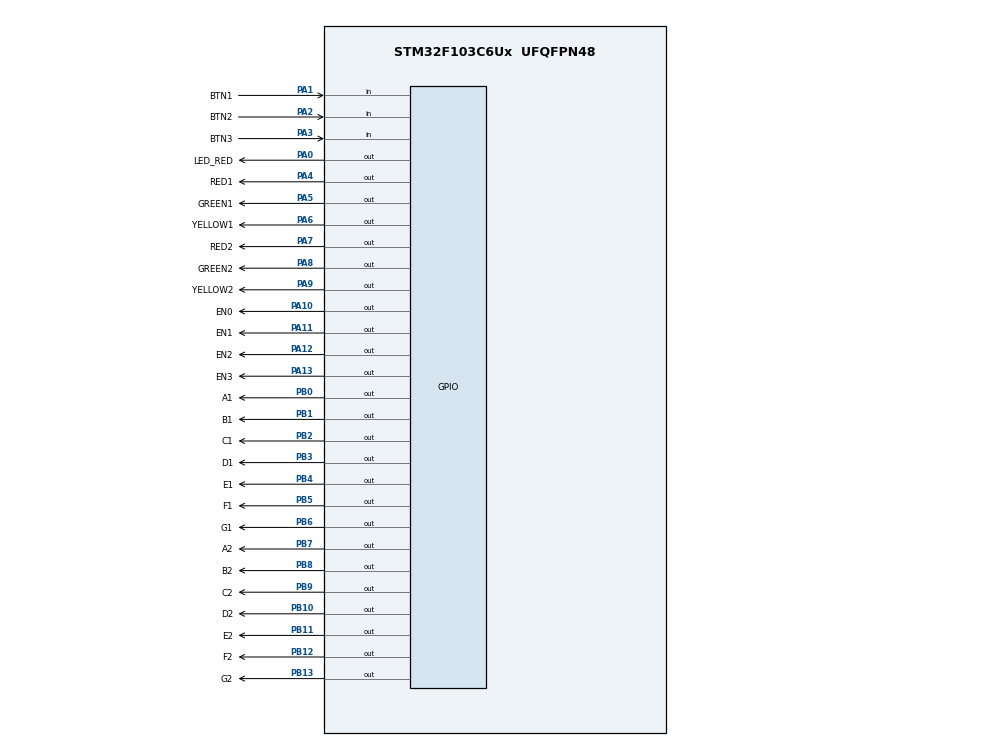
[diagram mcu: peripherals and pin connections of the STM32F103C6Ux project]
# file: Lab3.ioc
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Mcu.Family=STM32F1
Mcu.Name=STM32F103C6Ux
Mcu.Package=UFQFPN48
NVIC.PriorityGroup=NVIC_PRIORITYGROUP_4
NVIC.TIM2_IRQn=true\:0\:0\:false\:false\:true\:true\:true
PA0-WKUP.GPIO_Label=LED_RED
PA0-WKUP.Signal=GPIO_Output
PA1.GPIO_Label=BTN1
PA1.GPIO_PuPd=GPIO_PULLUP
PA1.Signal=GPIO_Input
PA10.GPIO_Label=EN0
PA10.Signal=GPIO_Output
PA11.GPIO_Label=EN1
PA11.Signal=GPIO_Output
PA12.GPIO_Label=EN2
PA12.Signal=GPIO_Output
PA13.GPIO_Label=EN3
PA13.Signal=GPIO_Output
PA2.GPIO_Label=BTN2
PA2.GPIO_PuPd=GPIO_PULLUP
PA2.Signal=GPIO_Input
PA3.GPIO_Label=BTN3
PA3.GPIO_PuPd=GPIO_PULLUP
PA3.Signal=GPIO_Input
PA4.GPIO_Label=RED1
PA4.Signal=GPIO_Output
PA5.GPIO_Label=GREEN1
PA5.Signal=GPIO_Output
PA6.GPIO_Label=YELLOW1
PA6.Signal=GPIO_Output
PA7.GPIO_Label=RED2
PA7.Signal=GPIO_Output
PA8.GPIO_Label=GREEN2
PA8.Signal=GPIO_Output
PA9.GPIO_Label=YELLOW2
PA9.Signal=GPIO_Output
PB0.GPIO_Label=A1
PB0.Signal=GPIO_Output
PB1.GPIO_Label=B1
PB1.Signal=GPIO_Output
PB10.GPIO_Label=D2
PB10.Signal=GPIO_Output
PB11.GPIO_Label=E2
PB11.Signal=GPIO_Output
PB12.GPIO_Label=F2
PB12.Signal=GPIO_Output
PB13.GPIO_Label=G2
PB13.Signal=GPIO_Output
PB2.GPIO_Label=C1
PB2.Signal=GPIO_Output
PB3.GPIO_Label=D1
PB3.Signal=GPIO_Output
PB4.GPIO_Label=E1
PB4.Signal=GPIO_Output
PB5.GPIO_Label=F1
PB5.Signal=GPIO_Output
PB6.GPIO_Label=G1
PB6.Signal=GPIO_Output
PB7.GPIO_Label=A2
PB7.Signal=GPIO_Output
PB8.GPIO_Label=B2
PB8.Signal=GPIO_Output
PB9.GPIO_Label=C2
PB9.Signal=GPIO_Output
ProjectManager.HeapSize=0x200
ProjectManager.StackSize=0x400
ProjectManager.TargetToolchain=STM32CubeIDE
RCC.APB1Freq_Value=8000000
RCC.APB2Freq_Value=8000000
TIM2.Period=9
TIM2.Prescaler=7999
VP_SYS_VS_ND.Mode=No_Debug
VP_TIM2_VS_ClockSourceINT.Mode=Internal
board=custom

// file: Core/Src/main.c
#include "main.h"
#include "global.h"

TIM_HandleTypeDef htim2;

void SystemClock_Config(void);
static void MX_TIM2_Init(void);
static void MX_GPIO_Init(void);

int main(void)
{
  HAL_Init();
  SystemClock_Config();
  MX_TIM2_Init();
  MX_GPIO_Init();

  HAL_TIM_Base_Start_IT(&htim2);

  setTimer(LED_RED, 100);
  setTimer(SEG_TIMER, 25);
  int SEG1 = 0;
  int SEG2 = 2;

  while (1)
  {
	  if (isTimerExpired(LED_RED)){
		  HAL_GPIO_TogglePin(LED_RED_GPIO_Port, LED_RED_Pin);
		  setTimer(LED_RED, 100);
	  }

	  if (isTimerExpired(SEG_TIMER)){
		  clearENs();
		  update7SEG(SEG1++);
		  update7SEG(SEG2++);
		  if (SEG1 >= 2) SEG1 = 0;
		  if (SEG2 >= 4) SEG2 = 2;
		  setTimer(SEG_TIMER, 25);
	  }
  }
}

void SystemClock_Config(void)
{
  RCC_OscInitTypeDef RCC_OscInitStruct = {0};
  RCC_ClkInitTypeDef RCC_ClkInitStruct = {0};

  /** Initializes the RCC Oscillators according to the specified parameters
  * in the RCC_OscInitTypeDef structure.
  */
  RCC_OscInitStruct.OscillatorType = RCC_OSCILLATORTYPE_HSI;
  RCC_OscInitStruct.HSIState = RCC_HSI_ON;
  RCC_OscInitStruct.HSICalibrationValue = RCC_HSICALIBRATION_DEFAULT;
  RCC_OscInitStruct.PLL.PLLState = RCC_PLL_NONE;
  if (HAL_RCC_OscConfig(&RCC_OscInitStruct) != HAL_OK)
  {
    Error_Handler();
  }
  /** Initializes the CPU, AHB and APB buses clocks
  */
  RCC_ClkInitStruct.ClockType = RCC_CLOCKTYPE_HCLK|RCC_CLOCKTYPE_SYSCLK
                              |RCC_CLOCKTYPE_PCLK1|RCC_CLOCKTYPE_PCLK2;
  RCC_ClkInitStruct.SYSCLKSource = RCC_SYSCLKSOURCE_HSI;
  RCC_ClkInitStruct.AHBCLKDivider = RCC_SYSCLK_DIV1;
  RCC_ClkInitStruct.APB1CLKDivider = RCC_HCLK_DIV1;
  RCC_ClkInitStruct.APB2CLKDivider = RCC_HCLK_DIV1;

  if (HAL_RCC_ClockConfig(&RCC_ClkInitStruct, FLASH_LATENCY_0) != HAL_OK)
  {
    Error_Handler();
  }
}

static void MX_TIM2_Init(void)
{

  TIM_ClockConfigTypeDef sClockSourceConfig = {0};
  TIM_MasterConfigTypeDef sMasterConfig = {0};

  htim2.Instance = TIM2;
  htim2.Init.Prescaler = 7999;
  htim2.Init.CounterMode = TIM_COUNTERMODE_UP;
  htim2.Init.Period = 9;
  htim2.Init.ClockDivision = TIM_CLOCKDIVISION_DIV1;
  htim2.Init.AutoReloadPreload = TIM_AUTORELOAD_PRELOAD_DISABLE;
  if (HAL_TIM_Base_Init(&htim2) != HAL_OK)
  {
    Error_Handler();
  }
  sClockSourceConfig.ClockSource = TIM_CLOCKSOURCE_INTERNAL;
  if (HAL_TIM_ConfigClockSource(&htim2, &sClockSourceConfig) != HAL_OK)
  {
    Error_Handler();
  }
  sMasterConfig.MasterOutputTrigger = TIM_TRGO_RESET;
  sMasterConfig.MasterSlaveMode = TIM_MASTERSLAVEMODE_DISABLE;
  if (HAL_TIMEx_MasterConfigSynchronization(&htim2, &sMasterConfig) != HAL_OK)
  {
    Error_Handler();
  }

}

static void MX_GPIO_Init(void)
{
  GPIO_InitTypeDef GPIO_InitStruct = {0};

  /* GPIO Ports Clock Enable */
  __HAL_RCC_GPIOA_CLK_ENABLE();
  __HAL_RCC_GPIOB_CLK_ENABLE();

  /*Configure GPIO pin Output Level */
  HAL_GPIO_WritePin(GPIOA, LED_RED_Pin|RED1_Pin|GREEN1_Pin|YELLOW1_Pin
                          |RED2_Pin|GREEN2_Pin|YELLOW2_Pin|EN0_Pin
                          |EN1_Pin|EN2_Pin|EN3_Pin, GPIO_PIN_RESET);

  /*Configure GPIO pin Output Level */
  HAL_GPIO_WritePin(GPIOB, A1_Pin|B1_Pin|C1_Pin|D2_Pin
                          |E2_Pin|F2_Pin|G2_Pin|D1_Pin
                          |E1_Pin|F1_Pin|G1_Pin|A2_Pin
                          |B2_Pin|C2_Pin, GPIO_PIN_RESET);

  /*Configure GPIO pins : LED_RED_Pin RED1_Pin GREEN1_Pin YELLOW1_Pin
                           RED2_Pin GREEN2_Pin YELLOW2_Pin EN0_Pin
                           EN1_Pin EN2_Pin EN3_Pin */
  GPIO_InitStruct.Pin = LED_RED_Pin|RED1_Pin|GREEN1_Pin|YELLOW1_Pin
                          |RED2_Pin|GREEN2_Pin|YELLOW2_Pin|EN0_Pin
                          |EN1_Pin|EN2_Pin|EN3_Pin;
  GPIO_InitStruct.Mode = GPIO_MODE_OUTPUT_PP;
  GPIO_InitStruct.Pull = GPIO_NOPULL;
  GPIO_InitStruct.Speed = GPIO_SPEED_FREQ_LOW;
  HAL_GPIO_Init(GPIOA, &GPIO_InitStruct);

  /*Configure GPIO pins : BTN1_Pin BTN2_Pin BTN3_Pin */
  GPIO_InitStruct.Pin = BTN1_Pin|BTN2_Pin|BTN3_Pin;
  GPIO_InitStruct.Mode = GPIO_MODE_INPUT;
  GPIO_InitStruct.Pull = GPIO_PULLUP;
  HAL_GPIO_Init(GPIOA, &GPIO_InitStruct);

  /*Configure GPIO pins : A1_Pin B1_Pin C1_Pin D2_Pin
                           E2_Pin F2_Pin G2_Pin D1_Pin
                           E1_Pin F1_Pin G1_Pin A2_Pin
                           B2_Pin C2_Pin */
  GPIO_InitStruct.Pin = A1_Pin|B1_Pin|C1_Pin|D2_Pin
                          |E2_Pin|F2_Pin|G2_Pin|D1_Pin
                          |E1_Pin|F1_Pin|G1_Pin|A2_Pin
                          |B2_Pin|C2_Pin;
  GPIO_InitStruct.Mode = GPIO_MODE_OUTPUT_PP;
  GPIO_InitStruct.Pull = GPIO_NOPULL;
  GPIO_InitStruct.Speed = GPIO_SPEED_FREQ_LOW;
  HAL_GPIO_Init(GPIOB, &GPIO_InitStruct);

}

/* USER CODE BEGIN 4 */
void HAL_TIM_PeriodElapsedCallback(TIM_HandleTypeDef *htim){
	timerRun();
	getKeyInput();
	fsm_automatic_run();
	fsm_manual_run();
}
/* USER CODE END 4 */

void Error_Handler(void)
{
  __disable_irq();
  while (1)
  {
  }
}

/************************ (C) COPYRIGHT STMicroelectronics *****END OF FILE****/
